# MSP430FR2433 register map
Vendor: msp430gen; File version: v0.4.0-29-g702f6f3-dirty
Registers are 16-bit, read-write, reset 0x0 unless marked. A register's access mark holds for its fields unless they carry their own. Offsets are from the block's base; [hi:lo] are bit positions; {n}, {i} and the like mark numbered series.

## FRCTL
Base 0x000001A0
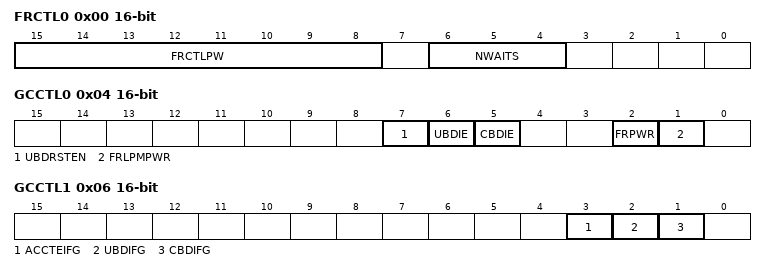
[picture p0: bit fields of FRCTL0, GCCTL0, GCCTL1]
0x00 FRCTL0 — FRAM Controller Control 0
  [15:8] FRCTLPW — FRCTLPW Password
    on read: 150=PASSWORD (Value always read from the FRCTL0 password) | on write: 165=PASSWORD (Value which must be written to the FRCTL0 password)
  [6:4] NWAITS — FRAM Wait state control Bit: 0
    0=WAIT0 (No wait state); 1=WAIT1 (1 wait state); {v}=WAIT{v} ({v} wait states) (v=2..7)
0x01 FRCTL0_H 8-bit (alternate view of FRCTL0) — FRAM Controller Control Register 0, upper byte
  [7:0] FRCTLPW — FRAM controller password
    on read: 150=PASSWORD (Value always read from the FRCTL0 password) | on write: 0=LOCK (Locks the FRAM controller registers again); 165=PASSWORD (Unlocks the FRAM controller registers)
0x04 GCCTL0 — General Control 0
  [7] UBDRSTEN — Enable Power Up Clear (PUC) reset if FRAM uncorrectable bit error detected
  [6] UBDIE — Enable NMI event if uncorrectable bit error detected
  [5] CBDIE — Enable NMI event if correctable bit error detected
  [2] FRPWR — FRAM Power Control
    0=DISABLED (FRAM power supply disabled); 1=ENABLED (FRAM power supply enabled)
  [1] FRLPMPWR — FRAM Enable FRAM auto power up after LPM
0x06 GCCTL1 — General Control 1
  [3] ACCTEIFG — Access time error flag
  [2] UBDIFG — FRAM uncorrectable bit error flag
  [1] CBDIFG — FRAM correctable bit error flag

## CRC
Base 0x000001C0
0x00 CRCDI — CRC Data In Register
  [15:0] CRCDI — CRC data in
0x00 CRCDI_L 8-bit (alternate view of CRCDI) — CRC Data In Register, lower byte
  [7:0] CRCDI — CRC data in, one byte
0x02 CRCDIRB — CRC data in reverse byte Register
  [15:0] CRCDIRB — CRC data in, bits reversed
0x02 CRCDIRB_L 8-bit (alternate view of CRCDIRB) — CRC Data In Reverse Byte Register, lower byte
  [7:0] CRCDIRB — CRC data in, one byte, bits reversed
0x04 CRCINIRES — CRC Initialisation Register and Result Register
  [15:0] CRCINIRES — CRC initialization (on write) and result (on read)
0x06 CRCRESR — CRC reverse result Register
  [15:0] CRCRESR ro — CRC result, bits reversed

## WDT_A
Base 0x000001CC
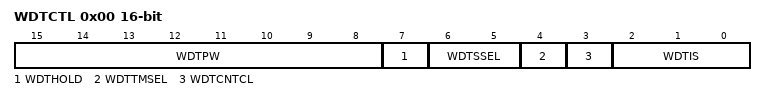
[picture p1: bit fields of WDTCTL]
0x00 WDTCTL — Watchdog Timer Control
  [15:8] WDTPW — Watchdog Timer Password
    on read: 105=PASSWORD (Value always read from the Watchdog Password field) | on write: 90=PASSWORD (Value which must be written to the Watchdog Password field)
  [7] WDTHOLD — WDT - Timer hold
    0=UNHOLD (Watchdog timer is not stopped); 1=HOLD (Watchdog timer is stopped)
  [6:5] WDTSSEL — WDT - Timer Clock Source Select 0
    0=SMCLK (WDT - Timer Clock Source Select: SMCLK); 1=ACLK (WDT - Timer Clock Source Select: ACLK); 2=VLOCLK (WDT - Timer Clock Source Select: VLOCLK); 3=BCLK (WDT - Timer Clock Source Select: Reserved)
  [4] WDTTMSEL — WDT - Timer Mode Select
  [3] WDTCNTCL — WDT - Timer Clear
  [2:0] WDTIS — WDT - Timer Interval Select 0
    0=/2G (Watchdog clock source / (2^(31)) (18:12:16 at 32.768 kHz)); 1=/128M (Watchdog clock source /(2^(27)) (01:08:16 at 32.768 kHz)); 2=/8192K (Watchdog clock source /(2^(23)) (00:04:16 at 32.768 kHz)); 3=/512K (Watchdog clock source /(2^(19)) (00:00:16 at 32.768 kHz)); 4=/32K (Watchdog clock source /(2^(15)) (1 s at 32.768 kHz)); 5=/8192 (Watchdog clock source / (2^(13)) (250 ms at 32.768 kHz)); 6=/512 (Watchdog clock source / (2^(9)) (15.625 ms at 32.768 kHz)); 7=/64 (Watchdog clock source / (2^(6)) (1.95 ms at 32.768 kHz))

## P1 — Port 1
Base 0x00000200
0x00 P1IN 8-bit — Port 1 Input register
0x02 P1OUT 8-bit — Port 1 Output register
0x04 P1DIR 8-bit — Port 1 Direction register
0x06 P1REN 8-bit — Port 1 Resistor Enable register
0x0A P1SEL0 8-bit — Port 1 Selection register bit 0
0x0C P1SEL1 8-bit — Port 1 Selection register bit 1
0x0E P1IV — Port 1 Interrupt Vector register
  [15:0] P1IV
    0=NONE (No interrupt pending); 2=IFG0 (Interrupt Source: Port 1.0 interrupt; Interrupt Flag: P1IFG0; Interrupt Priority: Highest); 4=IFG1 (Interrupt Source: Port 1.1 interrupt; Interrupt Flag: P1IFG1); 6=IFG2 (Interrupt Source: Port 1.2 interrupt; Interrupt Flag: P1IFG2); 8=IFG3 (Interrupt Source: Port 1.3 interrupt; Interrupt Flag: P1IFG3); 10=IFG4 (Interrupt Source: Port 1.4 interrupt; Interrupt Flag: P1IFG4); 12=IFG5 (Interrupt Source: Port 1.5 interrupt; Interrupt Flag: P1IFG5); 14=IFG6 (Interrupt Source: Port 1.6 interrupt; Interrupt Flag: P1IFG6); 16=IFG7 (Interrupt Source: Port 1.7 interrupt; Interrupt Flag: P1IFG7; Interrupt Priority: Lowest)
0x16 P1SELC 8-bit — Port 1 Complement Select register
0x18 P1IES 8-bit — Port 1 Interrupt Edge Select register
0x1A P1IE 8-bit — Port 1 Interrupt Enable register
0x1C P1IFG 8-bit — Port 1 Interrupt Flag register
